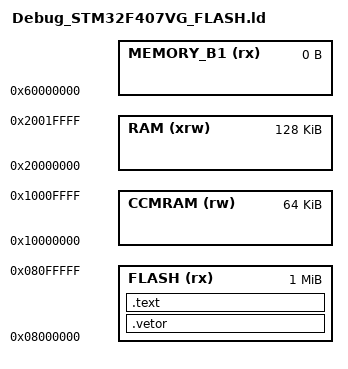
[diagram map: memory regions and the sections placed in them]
/*
******************************************************************************
File:     script.ld
Info:     Generated by Atollic TrueSTUDIO(R) 9.0.0   2018-05-14

Abstract: Linker script for STM32F407VG device
          Set heap size, stack size, stack location, memory areas and 
          sections according to application requirements. 

The MIT License (MIT)
Copyright (c) 2018 STMicroelectronics

Permission is hereby granted, free of charge, to any person obtaining a copy
of this software and associated documentation files (the "Software"), to deal
in the Software without restriction, including without limitation the rights
to use, copy, modify, merge, publish, distribute, sublicense, and/or sell
copies of the Software, and to permit persons to whom the Software is
furnished to do so, subject to the following conditions:

The above copyright notice and this permission notice shall be included in all
copies or substantial portions of the Software.

THE SOFTWARE IS PROVIDED "AS IS", WITHOUT WARRANTY OF ANY KIND, EXPRESS OR
IMPLIED, INCLUDING BUT NOT LIMITED TO THE WARRANTIES OF MERCHANTABILITY,
FITNESS FOR A PARTICULAR PURPOSE AND NONINFRINGEMENT. IN NO EVENT SHALL THE
AUTHORS OR COPYRIGHT HOLDERS BE LIABLE FOR ANY CLAIM, DAMAGES OR OTHER
LIABILITY, WHETHER IN AN ACTION OF CONTRACT, TORT OR OTHERWISE, ARISING FROM,
OUT OF OR IN CONNECTION WITH THE SOFTWARE OR THE USE OR OTHER DEALINGS IN THE
SOFTWARE.

******************************************************************************
*/

/* Entry Point */
ENTRY(inicio)

MEMORY
{
  FLASH (rx)      : ORIGIN = 0x08000000, LENGTH = 1024K
  RAM (xrw)       : ORIGIN = 0x20000000, LENGTH = 128K
  MEMORY_B1 (rx)  : ORIGIN = 0x60000000, LENGTH = 0K
  CCMRAM (rw)     : ORIGIN = 0x10000000, LENGTH = 64K
}

SECTIONS
{
	/* The startup code goes first into FLASH */
	.vetor :
	{
		. = ALIGN(4);
		*(.vetor)
		. = ALIGN(4);
  	} >FLASH
  
  	.text :
  	{
  		. = ALIGN;
  		*(.text)
  		*(.text*)
  		. = ALIGN(4);
  	} >FLASH
 }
